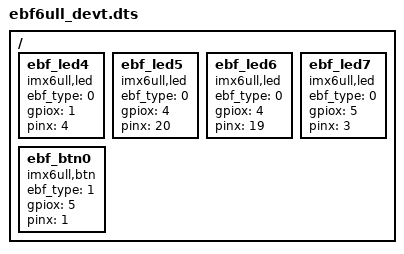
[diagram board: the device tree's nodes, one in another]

/************************************************
 * @file ebf6ull_devt.dts
 * @author Trisuborn (ttowfive@gmail.com)
 * @brief device tree for ebf6ull mini board.
 * @version 0.1
 * @date 2020-10-25
 * 
 * @copyright Copyright (c) 2020
 * 
 ************************************************/

#define EBF6ULL_LED_COMPATIBLE "imx6ull,led"

/* 根节点 */
/ {
    ebf_led4 {
        compatible = "imx6ull,led";
        ebf_type = <0>;
        gpiox = <1>;
        pinx  = <4>;
    };
    ebf_led5 {
        compatible = "imx6ull,led";
        ebf_type = <0>;
        gpiox = <4>;
        pinx  = <20>;
    };
    ebf_led6 {
        compatible = "imx6ull,led";
        ebf_type = <0>;
        gpiox = <4>;
        pinx  = <19>;
    };
    ebf_led7 {
        compatible = "imx6ull,led";
        ebf_type = <0>;
        gpiox = <5>;
        pinx  = <3>;
    };
    ebf_btn0 {
        compatible = "imx6ull,btn";
        ebf_type = <1>;
        gpiox = <5>;
        pinx  = <1>;
    };
    
};
